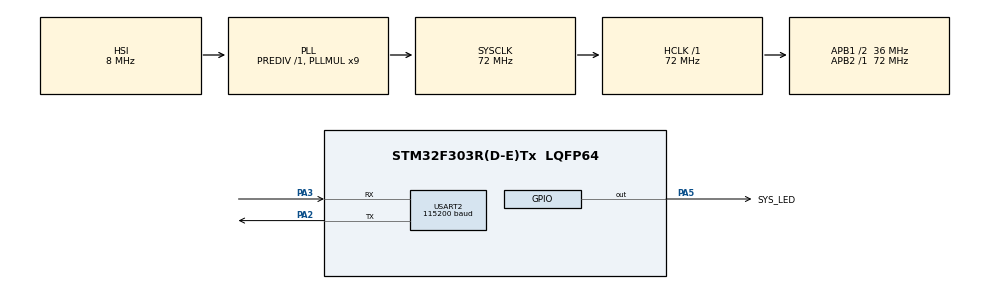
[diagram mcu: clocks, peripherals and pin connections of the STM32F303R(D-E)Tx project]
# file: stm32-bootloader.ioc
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Dma.Request0=USART2_RX
Dma.USART2_RX.0.Direction=DMA_PERIPH_TO_MEMORY
Dma.USART2_RX.0.Instance=DMA1_Channel6
Dma.USART2_RX.0.MemDataAlignment=DMA_MDATAALIGN_BYTE
Dma.USART2_RX.0.MemInc=DMA_MINC_ENABLE
Dma.USART2_RX.0.Mode=DMA_CIRCULAR
Dma.USART2_RX.0.PeriphDataAlignment=DMA_PDATAALIGN_BYTE
Dma.USART2_RX.0.PeriphInc=DMA_PINC_DISABLE
Dma.USART2_RX.0.Priority=DMA_PRIORITY_LOW
Mcu.Family=STM32F3
Mcu.Name=STM32F303R(D-E)Tx
Mcu.Package=LQFP64
NVIC.DMA1_Channel6_IRQn=true\:0\:0\:false\:false\:true\:false\:true\:true
NVIC.PriorityGroup=NVIC_PRIORITYGROUP_4
NVIC.USART2_IRQn=true\:0\:0\:false\:false\:true\:true\:true\:true
PA13.Mode=Serial_Wire
PA13.Signal=SYS_JTMS-SWDIO
PA14.Mode=Serial_Wire
PA14.Signal=SYS_JTCK-SWCLK
PA2.Mode=Asynchronous
PA2.Signal=USART2_TX
PA3.Mode=Asynchronous
PA3.Signal=USART2_RX
PA5.GPIO_Label=SYS_LED
PA5.Signal=GPIO_Output
ProjectManager.HeapSize=0x200
ProjectManager.StackSize=0x400
ProjectManager.TargetToolchain=STM32CubeIDE
RCC.AHBFreq_Value=72000000
RCC.APB1CLKDivider=RCC_HCLK_DIV2
RCC.APB1Freq_Value=36000000
RCC.APB1TimFreq_Value=72000000
RCC.APB2Freq_Value=72000000
RCC.APB2TimFreq_Value=72000000
RCC.CortexFreq_Value=72000000
RCC.HCLKFreq_Value=72000000
RCC.HSE_VALUE=8000000
RCC.HSI_VALUE=8000000
RCC.LSE_VALUE=32768
RCC.PLLMUL=RCC_PLL_MUL9
RCC.SYSCLKFreq_VALUE=72000000
RCC.SYSCLKSourceVirtual=RCC_SYSCLKSOURCE_PLLCLK
RCC.USBFreq_Value=72000000
USART2.BaudRate=115200
USART2.VirtualMode-Asynchronous=VM_ASYNC
board=custom

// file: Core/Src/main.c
/* USER CODE BEGIN Header */
/**
  ******************************************************************************
  * @file           : main.c
  * @brief          : Main program body
  ******************************************************************************
  * @attention
  *
  * Copyright (c) 2023 STMicroelectronics.
  * All rights reserved.
  *
  * This software is licensed under terms that can be found in the LICENSE file
  * in the root directory of this software component.
  * If no LICENSE file comes with this software, it is provided AS-IS.
  *
  ******************************************************************************
  */
/* USER CODE END Header */
#include "main.h"
#include "dma.h"
#include "usart.h"
#include "gpio.h"

/* USER CODE BEGIN Includes */
#include "led.h"
#include "main_process.h"
#include "usart_comm.h"
/* USER CODE END Includes */

/* USER CODE BEGIN PV */

extern sys_process_t sys_process;

/* USER CODE END PV */

void SystemClock_Config(void);

int main(void)
{
  /* USER CODE BEGIN 1 */

	uint8_t init_crc = 0;

  /* USER CODE END 1 */

  /* MCU Configuration--------------------------------------------------------*/

  /* Reset of all peripherals, Initializes the Flash interface and the Systick. */
  HAL_Init();

  /* Configure the system clock */
  SystemClock_Config();

  /* Initialize all configured peripherals */
  MX_GPIO_Init();
  MX_DMA_Init();
  MX_USART2_UART_Init();
  /* USER CODE BEGIN 2 */

  vLedProc(&sys_process);

  sys_process = BOOTLOADER;

  init_crc += initUsartDma();
  main_proc();

  /* USER CODE END 2 */

  /* Infinite loop */
  while (1)
  {

  }
}

void SystemClock_Config(void)
{
  RCC_OscInitTypeDef RCC_OscInitStruct = {0};
  RCC_ClkInitTypeDef RCC_ClkInitStruct = {0};
  RCC_PeriphCLKInitTypeDef PeriphClkInit = {0};

  /** Initializes the RCC Oscillators according to the specified parameters
  * in the RCC_OscInitTypeDef structure.
  */
  RCC_OscInitStruct.OscillatorType = RCC_OSCILLATORTYPE_HSI;
  RCC_OscInitStruct.HSIState = RCC_HSI_ON;
  RCC_OscInitStruct.HSICalibrationValue = RCC_HSICALIBRATION_DEFAULT;
  RCC_OscInitStruct.PLL.PLLState = RCC_PLL_ON;
  RCC_OscInitStruct.PLL.PLLSource = RCC_PLLSOURCE_HSI;
  RCC_OscInitStruct.PLL.PLLMUL = RCC_PLL_MUL9;
  RCC_OscInitStruct.PLL.PREDIV = RCC_PREDIV_DIV1;
  if (HAL_RCC_OscConfig(&RCC_OscInitStruct) != HAL_OK)
  {
    Error_Handler();
  }

  /** Initializes the CPU, AHB and APB buses clocks
  */
  RCC_ClkInitStruct.ClockType = RCC_CLOCKTYPE_HCLK|RCC_CLOCKTYPE_SYSCLK
                              |RCC_CLOCKTYPE_PCLK1|RCC_CLOCKTYPE_PCLK2;
  RCC_ClkInitStruct.SYSCLKSource = RCC_SYSCLKSOURCE_PLLCLK;
  RCC_ClkInitStruct.AHBCLKDivider = RCC_SYSCLK_DIV1;
  RCC_ClkInitStruct.APB1CLKDivider = RCC_HCLK_DIV2;
  RCC_ClkInitStruct.APB2CLKDivider = RCC_HCLK_DIV1;

  if (HAL_RCC_ClockConfig(&RCC_ClkInitStruct, FLASH_LATENCY_2) != HAL_OK)
  {
    Error_Handler();
  }
  PeriphClkInit.PeriphClockSelection = RCC_PERIPHCLK_USART2;
  PeriphClkInit.Usart2ClockSelection = RCC_USART2CLKSOURCE_PCLK1;
  if (HAL_RCCEx_PeriphCLKConfig(&PeriphClkInit) != HAL_OK)
  {
    Error_Handler();
  }
}

void Error_Handler(void)
{
  __disable_irq();
  while (1)
  {
  }
}
